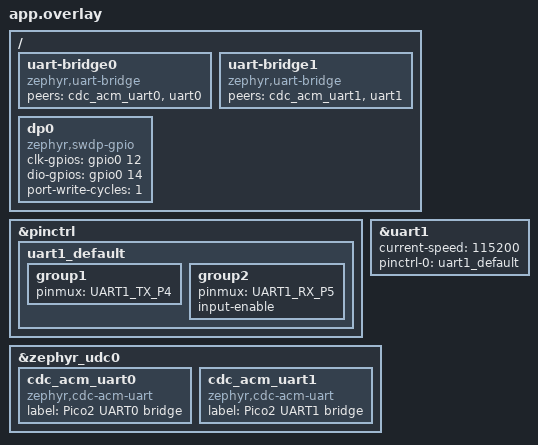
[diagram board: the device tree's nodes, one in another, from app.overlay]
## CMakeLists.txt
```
# SPDX-License-Identifier: Apache-2.0
#
# Raspberry Pi Pico 2 test firmware: 2x UART->USB CDC ACM + CMSIS-DAP SWD.

cmake_minimum_required(VERSION 3.28.0)
find_package(Zephyr REQUIRED HINTS $ENV{ZEPHYR_BASE})

project(pico2_uart_swd_test)

include(${ZEPHYR_BASE}/samples/subsys/usb/common/common.cmake)

target_sources(app PRIVATE
  src/main.c
)
```

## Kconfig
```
# SPDX-License-Identifier: Apache-2.0

mainmenu "Pico 2 UART/SWD test"

source "samples/subsys/usb/common/Kconfig.sample_usbd"

source "Kconfig.zephyr"
```

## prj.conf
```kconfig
# SPDX-License-Identifier: Apache-2.0

CONFIG_USB_DEVICE_STACK_NEXT=y
CONFIG_USBD_CDC_ACM_CLASS=y
CONFIG_CDC_ACM_SERIAL_INITIALIZE_AT_BOOT=n
CONFIG_USBD_CDC_ACM_LOG_LEVEL_OFF=y

CONFIG_SAMPLE_USBD_PID=0x0204
CONFIG_SAMPLE_USBD_PRODUCT="Pico2 2xUART+SWD test"
CONFIG_SAMPLE_USBD_MANUFACTURER="Radxa"
CONFIG_SAMPLE_USBD_SELF_POWERED=n
CONFIG_SAMPLE_USBD_MAX_POWER=100

CONFIG_DAP=y
CONFIG_DAP_BACKEND_USB=y
CONFIG_DAP_LOG_LEVEL_INF=y
CONFIG_DP_DRIVER_LOG_LEVEL_INF=y

CONFIG_GPIO=y
CONFIG_SERIAL=y
CONFIG_UART_INTERRUPT_DRIVEN=y
CONFIG_UART_LINE_CTRL=y
CONFIG_UART_USE_RUNTIME_CONFIGURE=y
CONFIG_UART_BRIDGE=y
CONFIG_UART_BRIDGE_BUF_SIZE=256

CONFIG_LOG=y
CONFIG_LOG_DEFAULT_LEVEL=2

# No UART console on purpose: the two hardware UARTs are exclusively
# owned by the CDC ACM bridges. Logs are only for a debug build with an
# external console attached.
CONFIG_CONSOLE=n
CONFIG_UART_CONSOLE=n
CONFIG_STDOUT_CONSOLE=n
```

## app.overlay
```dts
/*
 * SPDX-License-Identifier: Apache-2.0
 *
 * Raspberry Pi Pico 2 test build:
 *   UART0 (GP0 TX / GP1 RX) -> cdc_acm_uart0
 *   UART1 (GP4 TX / GP5 RX) -> cdc_acm_uart1
 *   SWD: SWCLK GP12, SWDIO GP14 (direct 3.3 V target connection)
 */

#include <zephyr/dt-bindings/gpio/gpio.h>
#include <zephyr/dt-bindings/pinctrl/rpi-pico-rp2350a-pinctrl.h>

/ {
	uart-bridge0 {
		compatible = "zephyr,uart-bridge";
		peers = <&cdc_acm_uart0 &uart0>;
	};

	uart-bridge1 {
		compatible = "zephyr,uart-bridge";
		peers = <&cdc_acm_uart1 &uart1>;
	};

	dp0 {
		compatible = "zephyr,swdp-gpio";
		status = "okay";
		clk-gpios = <&gpio0 12 GPIO_ACTIVE_HIGH>;
		dio-gpios = <&gpio0 14 GPIO_PULL_UP>;
		port-write-cycles = <1>;
	};
};

&pinctrl {
	uart1_default: uart1_default {
		group1 {
			pinmux = <UART1_TX_P4>;
		};

		group2 {
			pinmux = <UART1_RX_P5>;
			input-enable;
		};
	};
};

&uart1 {
	current-speed = <115200>;
	status = "okay";
	pinctrl-0 = <&uart1_default>;
	pinctrl-names = "default";
};

&zephyr_udc0 {
	cdc_acm_uart0: cdc_acm_uart0 {
		compatible = "zephyr,cdc-acm-uart";
		label = "Pico2 UART0 bridge";
	};

	cdc_acm_uart1: cdc_acm_uart1 {
		compatible = "zephyr,cdc-acm-uart";
		label = "Pico2 UART1 bridge";
	};
};
```

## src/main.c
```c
/*
 * SPDX-License-Identifier: Apache-2.0
 *
 * Runs the 2x CDC ACM UART bridges and the CMSIS-DAP SWD backend. No UART
 * console is enabled by default; logs are compiled in for debug builds.
 */

#include <zephyr/kernel.h>
#include <zephyr/dap/dap_link.h>
#include <zephyr/device.h>
#include <zephyr/usb/usbd.h>
#include <zephyr/logging/log.h>
#include <zephyr/drivers/uart/uart_bridge.h>

#include <sample_usbd.h>

LOG_MODULE_REGISTER(pico2_uart_swd_test, LOG_LEVEL_INF);

DAP_LINK_CONTEXT_DEFINE(pico2_dap_ctx, DEVICE_DT_GET_ONE(zephyr_swdp_gpio));

#define DEVICE_DT_GET_COMMA(node_id) DEVICE_DT_GET(node_id),

static const struct device *const uart_bridges[] = {
	DT_FOREACH_STATUS_OKAY(zephyr_uart_bridge, DEVICE_DT_GET_COMMA)
};

static void pico2_usb_msg_cb(struct usbd_context *const usbd_ctx,
			     const struct usbd_msg *const msg)
{
	if (msg->type == USBD_MSG_CDC_ACM_LINE_CODING ||
	    msg->type == USBD_MSG_CDC_ACM_CONTROL_LINE_STATE) {
		for (size_t i = 0; i < ARRAY_SIZE(uart_bridges); i++) {
			uart_bridge_settings_update(msg->dev, uart_bridges[i]);
		}
	}
}

int main(void)
{
	struct usbd_context *usbd;
	int ret;

	ret = dap_link_init(&pico2_dap_ctx);
	if (ret != 0) {
		LOG_ERR("DAP init failed: %d", ret);
		return ret;
	}

	ret = dap_link_backend_usb_init(&pico2_dap_ctx);
	if (ret != 0) {
		LOG_ERR("DAP USB backend init failed: %d", ret);
		return ret;
	}

	usbd = sample_usbd_init_device(pico2_usb_msg_cb);
	if (usbd == NULL) {
		LOG_ERR("USB setup failed");
		return -ENODEV;
	}

	if (!usbd_can_detect_vbus(usbd)) {
		ret = usbd_enable(usbd);
		if (ret != 0) {
			LOG_ERR("USB enable failed: %d", ret);
			return ret;
		}
	}

	LOG_INF("Pico2 2xUART+SWD test firmware ready");
	k_sleep(K_FOREVER);
	return 0;
}
```
